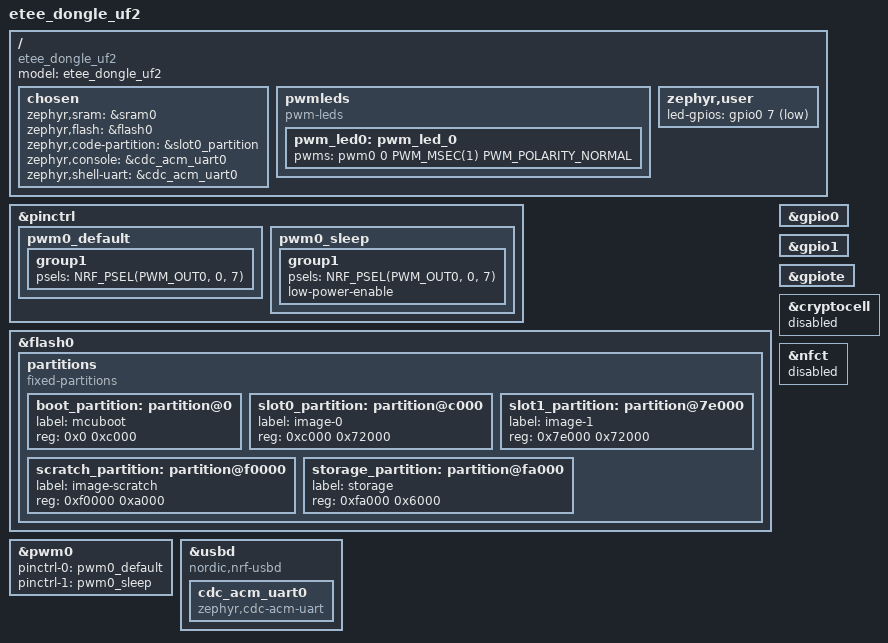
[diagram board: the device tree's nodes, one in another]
// Copyright (c) 2024 Nordic Semiconductor ASA
// SPDX-License-Identifier: Apache-2.0

/dts-v1/;
#include <nordic/nrf52840_qiaa.dtsi>

//move to dtsi?
&pinctrl {
	pwm0_default: pwm0_default {
		group1 {
			psels = <NRF_PSEL(PWM_OUT0, 0, 7)>;
		};
	};

	pwm0_sleep: pwm0_sleep {
		group1 {
			psels = <NRF_PSEL(PWM_OUT0, 0, 7)>;
			low-power-enable;
		};
	};
};
//end

/ {
	model = "etee_dongle_uf2";
	compatible = "etee_dongle_uf2";

	chosen {
		zephyr,sram = &sram0;
		zephyr,flash = &flash0;
		zephyr,code-partition = &slot0_partition;
		zephyr,console = &cdc_acm_uart0;
		zephyr,shell-uart = &cdc_acm_uart0;
	};

	pwmleds {
		compatible = "pwm-leds";
		pwm_led0: pwm_led_0 {
			pwms = <&pwm0 0 PWM_MSEC(1) PWM_POLARITY_NORMAL>;
		};
	};

	zephyr,user {
		led-gpios = <&gpio0 7 (GPIO_ACTIVE_LOW | GPIO_OPEN_DRAIN)>;
		// red 0.07, green 1.15, blue 1.09
		// TODO: but 0.07 is blue..
	};
};

&flash0 {
	partitions {
		compatible = "fixed-partitions";
		#address-cells = <1>;
		#size-cells = <1>;

		boot_partition: partition@0 {
			label = "mcuboot";
			reg = <0x0 0xc000>;
		};
		slot0_partition: partition@c000 {
			label = "image-0";
			reg = <0xc000 0x72000>;
		};
		slot1_partition: partition@7e000 {
			label = "image-1";
			reg = <0x7e000 0x72000>;
		};
		scratch_partition: partition@f0000 {
			label = "image-scratch";
			reg = <0xf0000 0xa000>;
		};
		storage_partition: partition@fa000 {
			label = "storage";
			reg = <0xfa000 0x6000>;
		};
	};
};

&gpio0 {
	status = "okay";
};

&gpio1 {
	status = "okay";
};

&gpiote {
	status = "okay";
};

&pwm0 {
	status = "okay";
	pinctrl-0 = <&pwm0_default>;
	pinctrl-1 = <&pwm0_sleep>;
	pinctrl-names = "default", "sleep";
};

zephyr_udc0: &usbd {
	compatible = "nordic,nrf-usbd";
	status = "okay";
	cdc_acm_uart0: cdc_acm_uart0 {
		compatible = "zephyr,cdc-acm-uart";
	};
};

&cryptocell {
	status = "disabled";
};

&nfct {
	status = "disabled";
};
